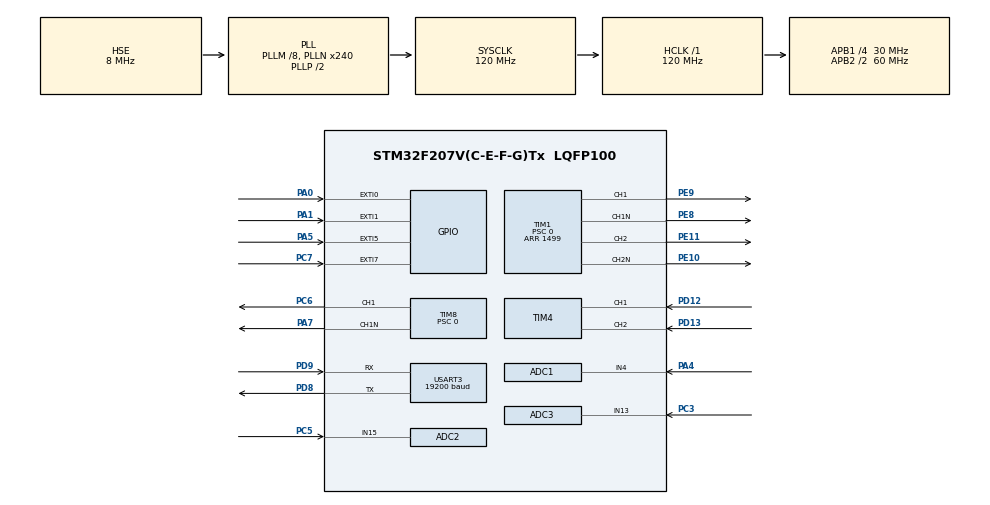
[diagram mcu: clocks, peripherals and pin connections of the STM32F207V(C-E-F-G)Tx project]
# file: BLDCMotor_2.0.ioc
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ADC1.Channel-0\#ChannelRegularConversion=ADC_CHANNEL_4
ADC1.ContinuousConvMode=ENABLE
ADC1.DMAContinuousRequests=ENABLE
ADC1.EOCSelection=ADC_EOC_SEQ_CONV
ADC1.Mode=ADC_TRIPLEMODE_REGSIMULT
ADC1.NbrOfConversion=1
ADC1.NbrOfConversionFlag=1
ADC1.Rank-0\#ChannelRegularConversion=1
ADC1.SamplingTime-0\#ChannelRegularConversion=ADC_SAMPLETIME_480CYCLES
ADC1.ScanConvMode=DISABLE
ADC1.master=1
ADC2.Channel-2\#ChannelRegularConversion=ADC_CHANNEL_15
ADC2.DMAAccessMode=ADC_DMAACCESSMODE_1
ADC2.Mode=ADC_TRIPLEMODE_REGSIMULT
ADC2.NbrOfConversionFlag=1
ADC2.Rank-2\#ChannelRegularConversion=1
ADC2.SamplingTime-2\#ChannelRegularConversion=ADC_SAMPLETIME_3CYCLES
ADC3.Channel-1\#ChannelRegularConversion=ADC_CHANNEL_13
ADC3.DMAAccessMode=ADC_DMAACCESSMODE_1
ADC3.Mode=ADC_TRIPLEMODE_REGSIMULT
ADC3.NbrOfConversionFlag=1
ADC3.Rank-1\#ChannelRegularConversion=1
ADC3.SamplingTime-1\#ChannelRegularConversion=ADC_SAMPLETIME_3CYCLES
Dma.ADC1.0.Direction=DMA_PERIPH_TO_MEMORY
Dma.ADC1.0.FIFOMode=DMA_FIFOMODE_DISABLE
Dma.ADC1.0.Instance=DMA2_Stream0
Dma.ADC1.0.MemDataAlignment=DMA_MDATAALIGN_HALFWORD
Dma.ADC1.0.MemInc=DMA_MINC_ENABLE
Dma.ADC1.0.Mode=DMA_CIRCULAR
Dma.ADC1.0.PeriphDataAlignment=DMA_PDATAALIGN_HALFWORD
Dma.ADC1.0.PeriphInc=DMA_PINC_DISABLE
Dma.ADC1.0.Priority=DMA_PRIORITY_LOW
Dma.Request0=ADC1
Mcu.Family=STM32F2
Mcu.Name=STM32F207V(C-E-F-G)Tx
Mcu.Package=LQFP100
NVIC.ADC_IRQn=true\:1\:0\:true\:false\:true\:true\:true\:true
NVIC.DMA2_Stream0_IRQn=true\:0\:0\:false\:false\:true\:false\:true\:true
NVIC.EXTI0_IRQn=true\:0\:0\:false\:false\:true\:true\:true\:true
NVIC.EXTI1_IRQn=true\:0\:0\:false\:false\:true\:true\:true\:true
NVIC.EXTI9_5_IRQn=true\:0\:0\:false\:false\:true\:true\:true\:true
NVIC.PriorityGroup=NVIC_PRIORITYGROUP_4
NVIC.TIM1_UP_TIM10_IRQn=true\:0\:0\:false\:false\:true\:true\:true\:true
NVIC.TIM3_IRQn=true\:0\:0\:false\:false\:true\:true\:true\:true
NVIC.TIM4_IRQn=true\:0\:0\:false\:false\:true\:true\:true\:true
NVIC.TIM8_TRG_COM_TIM14_IRQn=true\:0\:0\:false\:false\:true\:true\:true\:true
NVIC.USART3_IRQn=true\:0\:0\:false\:false\:true\:true\:true\:true
PA0-WKUP.GPIO_ModeDefaultEXTI=GPIO_MODE_IT_RISING_FALLING
PA0-WKUP.Signal=GPXTI0
PA1.GPIO_ModeDefaultEXTI=GPIO_MODE_IT_RISING_FALLING
PA1.Signal=GPXTI1
PA13.Mode=Serial_Wire
PA13.Signal=SYS_JTMS-SWDIO
PA14.Mode=Serial_Wire
PA14.Signal=SYS_JTCK-SWCLK
PA3.Signal=ADCx_IN3
PA4.Signal=ADCx_IN4
PA5.GPIO_ModeDefaultEXTI=GPIO_MODE_IT_RISING_FALLING
PA5.Signal=GPXTI5
PA7.Mode=PWM Generation1 CH1 CH1N
PA7.Signal=TIM8_CH1N
PA8.Signal=I2C3_SCL
PB1.Signal=ADCx_IN9
PC3.Signal=ADCx_IN13
PC4.Signal=ADCx_IN14
PC5.Signal=ADCx_IN15
PC6.Signal=S_TIM8_CH1
PC7.GPIO_ModeDefaultEXTI=GPIO_MODE_IT_RISING_FALLING
PC7.Signal=GPXTI7
PC9.Signal=I2C3_SDA
PD12.GPIO_PuPd=GPIO_PULLUP
PD12.Signal=S_TIM4_CH1
PD13.GPIO_PuPd=GPIO_PULLUP
PD13.Signal=S_TIM4_CH2
PD8.Mode=Asynchronous
PD8.Signal=USART3_TX
PD9.Mode=Asynchronous
PD9.Signal=USART3_RX
PE10.Mode=PWM Generation2 CH2 CH2N
PE10.Signal=TIM1_CH2N
PE11.Signal=S_TIM1_CH2
PE8.Mode=PWM Generation1 CH1 CH1N
PE8.Signal=TIM1_CH1N
PE9.Signal=S_TIM1_CH1
PH0-OSC_IN.Mode=HSE-External-Oscillator
PH0-OSC_IN.Signal=RCC_OSC_IN
PH1-OSC_OUT.Mode=HSE-External-Oscillator
PH1-OSC_OUT.Signal=RCC_OSC_OUT
ProjectManager.HeapSize=0x200
ProjectManager.StackSize=0x400
ProjectManager.TargetToolchain=STM32CubeIDE
RCC.48MHZClocksFreq_Value=60000000
RCC.AHBFreq_Value=120000000
RCC.APB1CLKDivider=RCC_HCLK_DIV4
RCC.APB1Freq_Value=30000000
RCC.APB1TimFreq_Value=60000000
RCC.APB2CLKDivider=RCC_HCLK_DIV2
RCC.APB2Freq_Value=60000000
RCC.APB2TimFreq_Value=120000000
RCC.CortexFreq_Value=120000000
RCC.HCLKFreq_Value=120000000
RCC.HSE_VALUE=8000000
RCC.HSI_VALUE=16000000
RCC.LSE_VALUE=32768
RCC.PLLM=8
RCC.PLLN=240
RCC.PLLSourceVirtual=RCC_PLLSOURCE_HSE
RCC.SYSCLKFreq_VALUE=120000000
RCC.SYSCLKSource=RCC_SYSCLKSOURCE_PLLCLK
RCC.VCOOutputFreq_Value=240000000
SH.ADCx_IN13.0=ADC1_IN13
SH.ADCx_IN13.1=ADC2_IN13
SH.ADCx_IN13.2=ADC3_IN13,IN13
SH.ADCx_IN14.0=ADC1_IN14
SH.ADCx_IN15.0=ADC1_IN15
SH.ADCx_IN15.1=ADC2_IN15,IN15
SH.ADCx_IN3.0=ADC1_IN3
SH.ADCx_IN4.0=ADC1_IN4,IN4
SH.ADCx_IN9.0=ADC1_IN9
SH.S_TIM1_CH1.0=TIM1_CH1,PWM Generation1 CH1 CH1N
SH.S_TIM1_CH2.0=TIM1_CH2,PWM Generation2 CH2 CH2N
SH.S_TIM4_CH1.0=TIM4_CH1,Encoder_Interface
SH.S_TIM4_CH2.0=TIM4_CH2,Encoder_Interface
SH.S_TIM8_CH1.0=TIM8_CH1,PWM Generation1 CH1 CH1N
TIM1.Channel-PWM\ Generation1\ CH1\ CH1N=TIM_CHANNEL_1
TIM1.Channel-PWM\ Generation2\ CH2\ CH2N=TIM_CHANNEL_2
TIM1.CounterMode=TIM_COUNTERMODE_CENTERALIGNED1
TIM1.DeadTime=128
TIM1.OCIdleState_2=TIM_OCIDLESTATE_RESET
TIM1.OCNIdleState_2=TIM_OCNIDLESTATE_RESET
TIM1.Period=1499
TIM1.Prescaler=0
TIM14.Channel=TIM_CHANNEL_1
TIM14.Period=14999
TIM14.Prescaler=0
TIM3.Period=9
TIM3.Prescaler=5999
TIM4.AutoReloadPreload=TIM_AUTORELOAD_PRELOAD_ENABLE
TIM4.EncoderMode=TIM_ENCODERMODE_TI12
TIM4.IC1Filter=10
TIM4.IC2Filter=10
TIM8.Channel-PWM\ Generation1\ CH1\ CH1N=TIM_CHANNEL_1
TIM8.CounterMode=TIM_COUNTERMODE_CENTERALIGNED1
TIM8.DeadTime=128
TIM8.Period=1499
TIM8.Prescaler=0
USART3.BaudRate=19200
USART3.VirtualMode=VM_ASYNC
VP_TIM14_VS_ClockSourceINT.Mode=Enable_Timer
VP_TIM14_VS_no_output1.Mode=Output Compare1 No Output
VP_TIM1_VS_ClockSourceINT.Mode=Internal
VP_TIM3_VS_ClockSourceINT.Mode=Internal
VP_TIM3_VS_OPM.Mode=OPM_bit
VP_TIM8_VS_ClockSourceINT.Mode=Internal
board=custom

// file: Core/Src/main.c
/* USER CODE BEGIN Header */
/**
  ******************************************************************************
  * @file           : main.c
  * @brief          : Main program body
  ******************************************************************************
  * @attention
  *
  * Copyright (c) 2024 STMicroelectronics.
  * All rights reserved.
  *
  * This software is licensed under terms that can be found in the LICENSE file
  * in the root directory of this software component.
  * If no LICENSE file comes with this software, it is provided AS-IS.
  *
  ******************************************************************************
  */
/* USER CODE END Header */
#include "main.h"

/* USER CODE BEGIN Includes */
#include "MotorControl.h"
/* USER CODE END Includes */

ADC_HandleTypeDef hadc1;
ADC_HandleTypeDef hadc2;
ADC_HandleTypeDef hadc3;
DMA_HandleTypeDef hdma_adc1;

TIM_HandleTypeDef htim1;
TIM_HandleTypeDef htim3;
TIM_HandleTypeDef htim4;
TIM_HandleTypeDef htim8;
TIM_HandleTypeDef htim14;

UART_HandleTypeDef huart3;

void SystemClock_Config(void);
static void MX_GPIO_Init(void);
static void MX_DMA_Init(void);
static void MX_ADC1_Init(void);
static void MX_TIM1_Init(void);
static void MX_TIM8_Init(void);
static void MX_TIM14_Init(void);
static void MX_TIM4_Init(void);
static void MX_ADC2_Init(void);
static void MX_ADC3_Init(void);
static void MX_USART3_UART_Init(void);
static void MX_TIM3_Init(void);

int main(void)
{

  /* MCU Configuration--------------------------------------------------------*/

  /* Reset of all peripherals, Initializes the Flash interface and the Systick. */
  HAL_Init();

  /* Configure the system clock */
  SystemClock_Config();

  /* Initialize all configured peripherals */
  MX_GPIO_Init();
  MX_DMA_Init();
  MX_ADC1_Init();
  MX_TIM1_Init();
  MX_TIM8_Init();
  MX_TIM14_Init();
  MX_TIM4_Init();
  MX_ADC2_Init();
  MX_ADC3_Init();
  MX_USART3_UART_Init();
  MX_TIM3_Init();
  /* USER CODE BEGIN 2 */
  start();

  /* USER CODE END 2 */

  /* Infinite loop */
  /* USER CODE BEGIN WHILE */
  while (1)
  {
	  loop();
    /* USER CODE END WHILE */

  }
}

void SystemClock_Config(void)
{
  RCC_OscInitTypeDef RCC_OscInitStruct = {0};
  RCC_ClkInitTypeDef RCC_ClkInitStruct = {0};

  /** Initializes the RCC Oscillators according to the specified parameters
  * in the RCC_OscInitTypeDef structure.
  */
  RCC_OscInitStruct.OscillatorType = RCC_OSCILLATORTYPE_HSE;
  RCC_OscInitStruct.HSEState = RCC_HSE_ON;
  RCC_OscInitStruct.PLL.PLLState = RCC_PLL_ON;
  RCC_OscInitStruct.PLL.PLLSource = RCC_PLLSOURCE_HSE;
  RCC_OscInitStruct.PLL.PLLM = 8;
  RCC_OscInitStruct.PLL.PLLN = 240;
  RCC_OscInitStruct.PLL.PLLP = RCC_PLLP_DIV2;
  RCC_OscInitStruct.PLL.PLLQ = 4;
  if (HAL_RCC_OscConfig(&RCC_OscInitStruct) != HAL_OK)
  {
    Error_Handler();
  }

  /** Initializes the CPU, AHB and APB buses clocks
  */
  RCC_ClkInitStruct.ClockType = RCC_CLOCKTYPE_HCLK|RCC_CLOCKTYPE_SYSCLK
                              |RCC_CLOCKTYPE_PCLK1|RCC_CLOCKTYPE_PCLK2;
  RCC_ClkInitStruct.SYSCLKSource = RCC_SYSCLKSOURCE_PLLCLK;
  RCC_ClkInitStruct.AHBCLKDivider = RCC_SYSCLK_DIV1;
  RCC_ClkInitStruct.APB1CLKDivider = RCC_HCLK_DIV4;
  RCC_ClkInitStruct.APB2CLKDivider = RCC_HCLK_DIV2;

  if (HAL_RCC_ClockConfig(&RCC_ClkInitStruct, FLASH_LATENCY_3) != HAL_OK)
  {
    Error_Handler();
  }
}

static void MX_ADC1_Init(void)
{

  ADC_MultiModeTypeDef multimode = {0};
  ADC_ChannelConfTypeDef sConfig = {0};

  /** Configure the global features of the ADC (Clock, Resolution, Data Alignment and number of conversion)
  */
  hadc1.Instance = ADC1;
  hadc1.Init.ClockPrescaler = ADC_CLOCK_SYNC_PCLK_DIV2;
  hadc1.Init.Resolution = ADC_RESOLUTION_12B;
  hadc1.Init.ScanConvMode = DISABLE;
  hadc1.Init.ContinuousConvMode = ENABLE;
  hadc1.Init.DiscontinuousConvMode = DISABLE;
  hadc1.Init.ExternalTrigConvEdge = ADC_EXTERNALTRIGCONVEDGE_NONE;
  hadc1.Init.ExternalTrigConv = ADC_SOFTWARE_START;
  hadc1.Init.DataAlign = ADC_DATAALIGN_RIGHT;
  hadc1.Init.NbrOfConversion = 1;
  hadc1.Init.DMAContinuousRequests = ENABLE;
  hadc1.Init.EOCSelection = ADC_EOC_SEQ_CONV;
  if (HAL_ADC_Init(&hadc1) != HAL_OK)
  {
    Error_Handler();
  }

  /** Configure the ADC multi-mode
  */
  multimode.Mode = ADC_TRIPLEMODE_REGSIMULT;
  multimode.DMAAccessMode = ADC_DMAACCESSMODE_1;
  multimode.TwoSamplingDelay = ADC_TWOSAMPLINGDELAY_5CYCLES;
  if (HAL_ADCEx_MultiModeConfigChannel(&hadc1, &multimode) != HAL_OK)
  {
    Error_Handler();
  }

  /** Configure for the selected ADC regular channel its corresponding rank in the sequencer and its sample time.
  */
  sConfig.Channel = ADC_CHANNEL_4;
  sConfig.Rank = 1;
  sConfig.SamplingTime = ADC_SAMPLETIME_480CYCLES;
  if (HAL_ADC_ConfigChannel(&hadc1, &sConfig) != HAL_OK)
  {
    Error_Handler();
  }

}

static void MX_ADC2_Init(void)
{

  ADC_ChannelConfTypeDef sConfig = {0};

  /** Configure the global features of the ADC (Clock, Resolution, Data Alignment and number of conversion)
  */
  hadc2.Instance = ADC2;
  hadc2.Init.ClockPrescaler = ADC_CLOCK_SYNC_PCLK_DIV2;
  hadc2.Init.Resolution = ADC_RESOLUTION_12B;
  hadc2.Init.ScanConvMode = DISABLE;
  hadc2.Init.ContinuousConvMode = ENABLE;
  hadc2.Init.DiscontinuousConvMode = DISABLE;
  hadc2.Init.DataAlign = ADC_DATAALIGN_RIGHT;
  hadc2.Init.NbrOfConversion = 1;
  hadc2.Init.DMAContinuousRequests = DISABLE;
  hadc2.Init.EOCSelection = ADC_EOC_SINGLE_CONV;
  if (HAL_ADC_Init(&hadc2) != HAL_OK)
  {
    Error_Handler();
  }

  /** Configure for the selected ADC regular channel its corresponding rank in the sequencer and its sample time.
  */
  sConfig.Channel = ADC_CHANNEL_15;
  sConfig.Rank = 1;
  sConfig.SamplingTime = ADC_SAMPLETIME_3CYCLES;
  if (HAL_ADC_ConfigChannel(&hadc2, &sConfig) != HAL_OK)
  {
    Error_Handler();
  }

}

static void MX_ADC3_Init(void)
{

  ADC_ChannelConfTypeDef sConfig = {0};

  /** Configure the global features of the ADC (Clock, Resolution, Data Alignment and number of conversion)
  */
  hadc3.Instance = ADC3;
  hadc3.Init.ClockPrescaler = ADC_CLOCK_SYNC_PCLK_DIV2;
  hadc3.Init.Resolution = ADC_RESOLUTION_12B;
  hadc3.Init.ScanConvMode = DISABLE;
  hadc3.Init.ContinuousConvMode = ENABLE;
  hadc3.Init.DiscontinuousConvMode = DISABLE;
  hadc3.Init.DataAlign = ADC_DATAALIGN_RIGHT;
  hadc3.Init.NbrOfConversion = 1;
  hadc3.Init.DMAContinuousRequests = DISABLE;
  hadc3.Init.EOCSelection = ADC_EOC_SINGLE_CONV;
  if (HAL_ADC_Init(&hadc3) != HAL_OK)
  {
    Error_Handler();
  }

  /** Configure for the selected ADC regular channel its corresponding rank in the sequencer and its sample time.
  */
  sConfig.Channel = ADC_CHANNEL_13;
  sConfig.Rank = 1;
  sConfig.SamplingTime = ADC_SAMPLETIME_3CYCLES;
  if (HAL_ADC_ConfigChannel(&hadc3, &sConfig) != HAL_OK)
  {
    Error_Handler();
  }

}

static void MX_TIM1_Init(void)
{

  TIM_ClockConfigTypeDef sClockSourceConfig = {0};
  TIM_MasterConfigTypeDef sMasterConfig = {0};
  TIM_OC_InitTypeDef sConfigOC = {0};
  TIM_BreakDeadTimeConfigTypeDef sBreakDeadTimeConfig = {0};

  htim1.Instance = TIM1;
  htim1.Init.Prescaler = 0;
  htim1.Init.CounterMode = TIM_COUNTERMODE_CENTERALIGNED1;
  htim1.Init.Period = 1499;
  htim1.Init.ClockDivision = TIM_CLOCKDIVISION_DIV1;
  htim1.Init.RepetitionCounter = 0;
  htim1.Init.AutoReloadPreload = TIM_AUTORELOAD_PRELOAD_DISABLE;
  if (HAL_TIM_Base_Init(&htim1) != HAL_OK)
  {
    Error_Handler();
  }
  sClockSourceConfig.ClockSource = TIM_CLOCKSOURCE_INTERNAL;
  if (HAL_TIM_ConfigClockSource(&htim1, &sClockSourceConfig) != HAL_OK)
  {
    Error_Handler();
  }
  if (HAL_TIM_PWM_Init(&htim1) != HAL_OK)
  {
    Error_Handler();
  }
  sMasterConfig.MasterOutputTrigger = TIM_TRGO_RESET;
  sMasterConfig.MasterSlaveMode = TIM_MASTERSLAVEMODE_DISABLE;
  if (HAL_TIMEx_MasterConfigSynchronization(&htim1, &sMasterConfig) != HAL_OK)
  {
    Error_Handler();
  }
  sConfigOC.OCMode = TIM_OCMODE_PWM1;
  sConfigOC.Pulse = 0;
  sConfigOC.OCPolarity = TIM_OCPOLARITY_HIGH;
  sConfigOC.OCNPolarity = TIM_OCNPOLARITY_HIGH;
  sConfigOC.OCFastMode = TIM_OCFAST_DISABLE;
  sConfigOC.OCIdleState = TIM_OCIDLESTATE_RESET;
  sConfigOC.OCNIdleState = TIM_OCNIDLESTATE_RESET;
  if (HAL_TIM_PWM_ConfigChannel(&htim1, &sConfigOC, TIM_CHANNEL_1) != HAL_OK)
  {
    Error_Handler();
  }
  if (HAL_TIM_PWM_ConfigChannel(&htim1, &sConfigOC, TIM_CHANNEL_2) != HAL_OK)
  {
    Error_Handler();
  }
  sBreakDeadTimeConfig.OffStateRunMode = TIM_OSSR_DISABLE;
  sBreakDeadTimeConfig.OffStateIDLEMode = TIM_OSSI_DISABLE;
  sBreakDeadTimeConfig.LockLevel = TIM_LOCKLEVEL_OFF;
  sBreakDeadTimeConfig.DeadTime = 128;
  sBreakDeadTimeConfig.BreakState = TIM_BREAK_DISABLE;
  sBreakDeadTimeConfig.BreakPolarity = TIM_BREAKPOLARITY_HIGH;
  sBreakDeadTimeConfig.AutomaticOutput = TIM_AUTOMATICOUTPUT_DISABLE;
  if (HAL_TIMEx_ConfigBreakDeadTime(&htim1, &sBreakDeadTimeConfig) != HAL_OK)
  {
    Error_Handler();
  }
  HAL_TIM_MspPostInit(&htim1);

}

static void MX_TIM3_Init(void)
{

  TIM_ClockConfigTypeDef sClockSourceConfig = {0};
  TIM_MasterConfigTypeDef sMasterConfig = {0};

  htim3.Instance = TIM3;
  htim3.Init.Prescaler = 5999;
  htim3.Init.CounterMode = TIM_COUNTERMODE_UP;
  htim3.Init.Period = 9;
  htim3.Init.ClockDivision = TIM_CLOCKDIVISION_DIV1;
  htim3.Init.AutoReloadPreload = TIM_AUTORELOAD_PRELOAD_DISABLE;
  if (HAL_TIM_Base_Init(&htim3) != HAL_OK)
  {
    Error_Handler();
  }
  sClockSourceConfig.ClockSource = TIM_CLOCKSOURCE_INTERNAL;
  if (HAL_TIM_ConfigClockSource(&htim3, &sClockSourceConfig) != HAL_OK)
  {
    Error_Handler();
  }
  if (HAL_TIM_OnePulse_Init(&htim3, TIM_OPMODE_SINGLE) != HAL_OK)
  {
    Error_Handler();
  }
  sMasterConfig.MasterOutputTrigger = TIM_TRGO_RESET;
  sMasterConfig.MasterSlaveMode = TIM_MASTERSLAVEMODE_DISABLE;
  if (HAL_TIMEx_MasterConfigSynchronization(&htim3, &sMasterConfig) != HAL_OK)
  {
    Error_Handler();
  }

}

static void MX_TIM4_Init(void)
{

  TIM_Encoder_InitTypeDef sConfig = {0};
  TIM_MasterConfigTypeDef sMasterConfig = {0};

  htim4.Instance = TIM4;
  htim4.Init.Prescaler = 0;
  htim4.Init.CounterMode = TIM_COUNTERMODE_UP;
  htim4.Init.Period = 65535;
  htim4.Init.ClockDivision = TIM_CLOCKDIVISION_DIV1;
  htim4.Init.AutoReloadPreload = TIM_AUTORELOAD_PRELOAD_ENABLE;
  sConfig.EncoderMode = TIM_ENCODERMODE_TI12;
  sConfig.IC1Polarity = TIM_ICPOLARITY_RISING;
  sConfig.IC1Selection = TIM_ICSELECTION_DIRECTTI;
  sConfig.IC1Prescaler = TIM_ICPSC_DIV1;
  sConfig.IC1Filter = 10;
  sConfig.IC2Polarity = TIM_ICPOLARITY_RISING;
  sConfig.IC2Selection = TIM_ICSELECTION_DIRECTTI;
  sConfig.IC2Prescaler = TIM_ICPSC_DIV1;
  sConfig.IC2Filter = 10;
  if (HAL_TIM_Encoder_Init(&htim4, &sConfig) != HAL_OK)
  {
    Error_Handler();
  }
  sMasterConfig.MasterOutputTrigger = TIM_TRGO_RESET;
  sMasterConfig.MasterSlaveMode = TIM_MASTERSLAVEMODE_DISABLE;
  if (HAL_TIMEx_MasterConfigSynchronization(&htim4, &sMasterConfig) != HAL_OK)
  {
    Error_Handler();
  }

}

static void MX_TIM8_Init(void)
{

  TIM_ClockConfigTypeDef sClockSourceConfig = {0};
  TIM_MasterConfigTypeDef sMasterConfig = {0};
  TIM_OC_InitTypeDef sConfigOC = {0};
  TIM_BreakDeadTimeConfigTypeDef sBreakDeadTimeConfig = {0};

  htim8.Instance = TIM8;
  htim8.Init.Prescaler = 0;
  htim8.Init.CounterMode = TIM_COUNTERMODE_CENTERALIGNED1;
  htim8.Init.Period = 1499;
  htim8.Init.ClockDivision = TIM_CLOCKDIVISION_DIV1;
  htim8.Init.RepetitionCounter = 0;
  htim8.Init.AutoReloadPreload = TIM_AUTORELOAD_PRELOAD_DISABLE;
  if (HAL_TIM_Base_Init(&htim8) != HAL_OK)
  {
    Error_Handler();
  }
  sClockSourceConfig.ClockSource = TIM_CLOCKSOURCE_INTERNAL;
  if (HAL_TIM_ConfigClockSource(&htim8, &sClockSourceConfig) != HAL_OK)
  {
    Error_Handler();
  }
  if (HAL_TIM_PWM_Init(&htim8) != HAL_OK)
  {
    Error_Handler();
  }
  sMasterConfig.MasterOutputTrigger = TIM_TRGO_RESET;
  sMasterConfig.MasterSlaveMode = TIM_MASTERSLAVEMODE_DISABLE;
  if (HAL_TIMEx_MasterConfigSynchronization(&htim8, &sMasterConfig) != HAL_OK)
  {
    Error_Handler();
  }
  sConfigOC.OCMode = TIM_OCMODE_PWM1;
  sConfigOC.Pulse = 0;
  sConfigOC.OCPolarity = TIM_OCPOLARITY_HIGH;
  sConfigOC.OCNPolarity = TIM_OCNPOLARITY_HIGH;
  sConfigOC.OCFastMode = TIM_OCFAST_DISABLE;
  sConfigOC.OCIdleState = TIM_OCIDLESTATE_RESET;
  sConfigOC.OCNIdleState = TIM_OCNIDLESTATE_RESET;
  if (HAL_TIM_PWM_ConfigChannel(&htim8, &sConfigOC, TIM_CHANNEL_1) != HAL_OK)
  {
    Error_Handler();
  }
  sBreakDeadTimeConfig.OffStateRunMode = TIM_OSSR_DISABLE;
  sBreakDeadTimeConfig.OffStateIDLEMode = TIM_OSSI_DISABLE;
  sBreakDeadTimeConfig.LockLevel = TIM_LOCKLEVEL_OFF;
  sBreakDeadTimeConfig.DeadTime = 128;
  sBreakDeadTimeConfig.BreakState = TIM_BREAK_DISABLE;
  sBreakDeadTimeConfig.BreakPolarity = TIM_BREAKPOLARITY_HIGH;
  sBreakDeadTimeConfig.AutomaticOutput = TIM_AUTOMATICOUTPUT_DISABLE;
  if (HAL_TIMEx_ConfigBreakDeadTime(&htim8, &sBreakDeadTimeConfig) != HAL_OK)
  {
    Error_Handler();
  }
  HAL_TIM_MspPostInit(&htim8);

}

static void MX_TIM14_Init(void)
{

  TIM_OC_InitTypeDef sConfigOC = {0};

  htim14.Instance = TIM14;
  htim14.Init.Prescaler = 0;
  htim14.Init.CounterMode = TIM_COUNTERMODE_UP;
  htim14.Init.Period = 14999;
  htim14.Init.ClockDivision = TIM_CLOCKDIVISION_DIV1;
  htim14.Init.AutoReloadPreload = TIM_AUTORELOAD_PRELOAD_DISABLE;
  if (HAL_TIM_Base_Init(&htim14) != HAL_OK)
  {
    Error_Handler();
  }
  if (HAL_TIM_OC_Init(&htim14) != HAL_OK)
  {
    Error_Handler();
  }
  sConfigOC.OCMode = TIM_OCMODE_TIMING;
  sConfigOC.Pulse = 0;
  sConfigOC.OCPolarity = TIM_OCPOLARITY_HIGH;
  sConfigOC.OCFastMode = TIM_OCFAST_DISABLE;
  if (HAL_TIM_OC_ConfigChannel(&htim14, &sConfigOC, TIM_CHANNEL_1) != HAL_OK)
  {
    Error_Handler();
  }

}

static void MX_USART3_UART_Init(void)
{

  huart3.Instance = USART3;
  huart3.Init.BaudRate = 19200;
  huart3.Init.WordLength = UART_WORDLENGTH_8B;
  huart3.Init.StopBits = UART_STOPBITS_1;
  huart3.Init.Parity = UART_PARITY_NONE;
  huart3.Init.Mode = UART_MODE_TX_RX;
  huart3.Init.HwFlowCtl = UART_HWCONTROL_NONE;
  huart3.Init.OverSampling = UART_OVERSAMPLING_16;
  if (HAL_UART_Init(&huart3) != HAL_OK)
  {
    Error_Handler();
  }

}

static void MX_DMA_Init(void)
{

  /* DMA controller clock enable */
  __HAL_RCC_DMA2_CLK_ENABLE();

  /* DMA interrupt init */
  /* DMA2_Stream0_IRQn interrupt configuration */
  HAL_NVIC_SetPriority(DMA2_Stream0_IRQn, 0, 0);
  HAL_NVIC_EnableIRQ(DMA2_Stream0_IRQn);

}

static void MX_GPIO_Init(void)
{
  GPIO_InitTypeDef GPIO_InitStruct = {0};

  /* GPIO Ports Clock Enable */
  __HAL_RCC_GPIOH_CLK_ENABLE();
  __HAL_RCC_GPIOC_CLK_ENABLE();
  __HAL_RCC_GPIOA_CLK_ENABLE();
  __HAL_RCC_GPIOB_CLK_ENABLE();
  __HAL_RCC_GPIOE_CLK_ENABLE();
  __HAL_RCC_GPIOD_CLK_ENABLE();

  /*Configure GPIO pins : PA0 PA1 PA5 */
  GPIO_InitStruct.Pin = GPIO_PIN_0|GPIO_PIN_1|GPIO_PIN_5;
  GPIO_InitStruct.Mode = GPIO_MODE_IT_RISING_FALLING;
  GPIO_InitStruct.Pull = GPIO_NOPULL;
  HAL_GPIO_Init(GPIOA, &GPIO_InitStruct);

  /*Configure GPIO pin : PC7 */
  GPIO_InitStruct.Pin = GPIO_PIN_7;
  GPIO_InitStruct.Mode = GPIO_MODE_IT_RISING_FALLING;
  GPIO_InitStruct.Pull = GPIO_NOPULL;
  HAL_GPIO_Init(GPIOC, &GPIO_InitStruct);

  /*Configure GPIO pin : PC9 */
  GPIO_InitStruct.Pin = GPIO_PIN_9;
  GPIO_InitStruct.Mode = GPIO_MODE_AF_OD;
  GPIO_InitStruct.Pull = GPIO_NOPULL;
  GPIO_InitStruct.Speed = GPIO_SPEED_FREQ_VERY_HIGH;
  GPIO_InitStruct.Alternate = GPIO_AF4_I2C3;
  HAL_GPIO_Init(GPIOC, &GPIO_InitStruct);

  /*Configure GPIO pin : PA8 */
  GPIO_InitStruct.Pin = GPIO_PIN_8;
  GPIO_InitStruct.Mode = GPIO_MODE_AF_OD;
  GPIO_InitStruct.Pull = GPIO_NOPULL;
  GPIO_InitStruct.Speed = GPIO_SPEED_FREQ_VERY_HIGH;
  GPIO_InitStruct.Alternate = GPIO_AF4_I2C3;
  HAL_GPIO_Init(GPIOA, &GPIO_InitStruct);

  /* EXTI interrupt init*/
  HAL_NVIC_SetPriority(EXTI0_IRQn, 0, 0);
  HAL_NVIC_EnableIRQ(EXTI0_IRQn);

  HAL_NVIC_SetPriority(EXTI1_IRQn, 0, 0);
  HAL_NVIC_EnableIRQ(EXTI1_IRQn);

  HAL_NVIC_SetPriority(EXTI9_5_IRQn, 0, 0);
  HAL_NVIC_EnableIRQ(EXTI9_5_IRQn);

}

void Error_Handler(void)
{
  __disable_irq();
  while (1)
  {
  }
}
